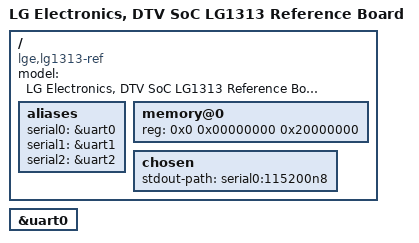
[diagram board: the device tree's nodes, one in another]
// SPDX-License-Identifier: GPL-2.0
/*
 * dts file for lg1313 Reference Board.
 *
 * Copyright (C) 2016, LG Electronics
 */

/dts-v1/;

#include "lg1313.dtsi"

/ {
	#address-cells = <2>;
	#size-cells = <1>;

	model = "LG Electronics, DTV SoC LG1313 Reference Board";
	compatible = "lge,lg1313-ref", "lge,lg1313";

	aliases {
		serial0 = &uart0;
		serial1 = &uart1;
		serial2 = &uart2;
	};

	memory@0 {
		device_type = "memory";
		reg = <0x0 0x00000000 0x20000000>;
	};

	chosen {
		stdout-path = "serial0:115200n8";
	};
};

&uart0 {
	status = "okay";
};
